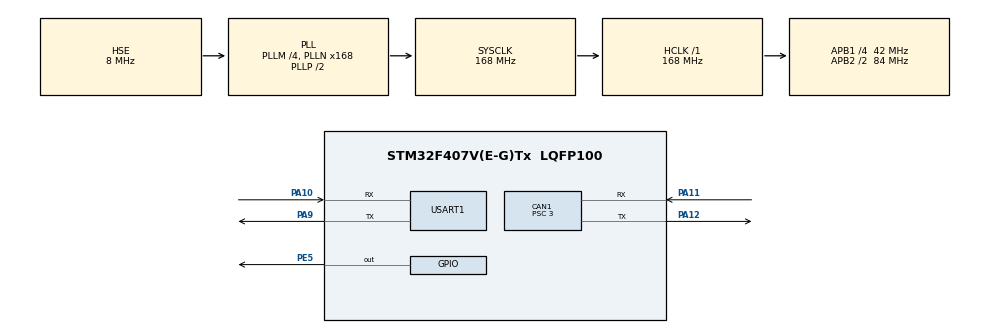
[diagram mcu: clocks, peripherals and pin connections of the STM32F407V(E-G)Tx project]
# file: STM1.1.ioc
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CAN1.BS1=CAN_BS1_10TQ
CAN1.BS2=CAN_BS2_3TQ
CAN1.CalculateBaudRate=1000000
CAN1.CalculateTimeBit=1000
CAN1.CalculateTimeQuantum=71.42857142857143
CAN1.Mode=CAN_MODE_SILENT_LOOPBACK
CAN1.Prescaler=3
Mcu.Family=STM32F4
Mcu.Name=STM32F407V(E-G)Tx
Mcu.Package=LQFP100
NVIC.CAN1_RX0_IRQn=true\:0\:0\:false\:false\:true\:true\:true\:true
NVIC.CAN1_TX_IRQn=true\:0\:0\:false\:false\:true\:true\:true\:true
NVIC.PriorityGroup=NVIC_PRIORITYGROUP_4
NVIC.USART1_IRQn=true\:0\:0\:false\:false\:true\:true\:true\:true
PA10.Mode=Asynchronous
PA10.Signal=USART1_RX
PA11.Mode=CAN_Activate
PA11.Signal=CAN1_RX
PA12.Mode=CAN_Activate
PA12.Signal=CAN1_TX
PA13.Mode=Serial_Wire
PA13.Signal=SYS_JTMS-SWDIO
PA14.Mode=Serial_Wire
PA14.Signal=SYS_JTCK-SWCLK
PA9.Mode=Asynchronous
PA9.Signal=USART1_TX
PE5.Signal=GPIO_Output
PH0-OSC_IN.Mode=HSE-External-Oscillator
PH0-OSC_IN.Signal=RCC_OSC_IN
PH1-OSC_OUT.Mode=HSE-External-Oscillator
PH1-OSC_OUT.Signal=RCC_OSC_OUT
ProjectManager.HeapSize=0x200
ProjectManager.StackSize=0x400
ProjectManager.TargetToolchain=CMake
RCC.48MHZClocksFreq_Value=84000000
RCC.AHBFreq_Value=168000000
RCC.APB1CLKDivider=RCC_HCLK_DIV4
RCC.APB1Freq_Value=42000000
RCC.APB1TimFreq_Value=84000000
RCC.APB2CLKDivider=RCC_HCLK_DIV2
RCC.APB2Freq_Value=84000000
RCC.APB2TimFreq_Value=168000000
RCC.CortexFreq_Value=168000000
RCC.HCLKFreq_Value=168000000
RCC.HSE_VALUE=8000000
RCC.HSI_VALUE=16000000
RCC.LSE_VALUE=32768
RCC.PLLM=4
RCC.PLLN=168
RCC.PLLSourceVirtual=RCC_PLLSOURCE_HSE
RCC.SYSCLKFreq_VALUE=168000000
RCC.SYSCLKSource=RCC_SYSCLKSOURCE_PLLCLK
RCC.VCOOutputFreq_Value=336000000
TIM9.Period=250-1
TIM9.Prescaler=84-1
USART1.VirtualMode=VM_ASYNC
VP_TIM9_VS_ClockSourceINT.Mode=Internal
board=custom

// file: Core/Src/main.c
/* USER CODE BEGIN Header */
/**
  ******************************************************************************
  * @file           : main.c
  * @brief          : Main program body
  ******************************************************************************
  * @attention
  *
  * Copyright (c) 2026 STMicroelectronics.
  * All rights reserved.
  *
  * This software is licensed under terms that can be found in the LICENSE file
  * in the root directory of this software component.
  * If no LICENSE file comes with this software, it is provided AS-IS.
  *
  ******************************************************************************
  */
/* USER CODE END Header */
#include "main.h"
#include "can.h"
#include "tim.h"
#include "usart.h"
#include "gpio.h"

/* USER CODE BEGIN PV */
// uint8_t receiveData [2];
/* USER CODE END PV */

void SystemClock_Config(void);

/* USER CODE BEGIN 0 */
// void HAL_UART_RxCpltCallback(UART_HandleTypeDef *huart){
//   HAL_UART_Transmit_IT(&huart1, receiveData, 2);
//     GPIO_PinState state = GPIO_PIN_SET;
//     if (receiveData[1] == '0')
//     {
//       state = GPIO_PIN_RESET;
//     }
//     if (receiveData[0] == 'R')
//     {
//       HAL_GPIO_WritePin(LED_RED_GPIO_Port, LED_RED_Pin, state);

//     }
//     else if (receiveData[0] == 'G')
//     {
//       HAL_GPIO_WritePin(LED_GREEN_GPIO_Port, LED_GREEN_Pin, state);
//     }
//     HAL_UART_Receive_IT(&huart1, receiveData, 2);
// }

/* USER CODE END 0 */

int main(void)
{

  /* MCU Configuration--------------------------------------------------------*/

  /* Reset of all peripherals, Initializes the Flash interface and the Systick. */
  HAL_Init();

  /* Configure the system clock */
  SystemClock_Config();

  /* Initialize all configured peripherals */
  MX_GPIO_Init();
  MX_TIM9_Init();
  MX_USART1_UART_Init();
  MX_CAN1_Init();
  /* USER CODE BEGIN 2 */
  // HAL_UART_Receive_IT(&huart1, receiveData, 2);

  CAN_TxHeaderTypeDef txHeader = {0};
  txHeader.StdId = 0x713;// TODO 对吗
  txHeader.ExtId = 0;// TODO对吗
  txHeader.IDE = CAN_ID_STD;// TODO 不对吧
  txHeader.RTR = CAN_RTR_DATA;//TODO 要改吗
  txHeader.DLC = 6;// TODO 要改吗
  txHeader.TransmitGlobalTime = DISABLE;
  /* 0x201 M2006 current, big-endian int16, range typically [-10000, 10000] */
  uint8_t txData[8] = {};// TODO 构造控制电机的CAN帧。建议电流值：1000
  uint32_t txMailbox;
  /* USER CODE END 2 */

  /* Infinite loop */
  /* USER CODE BEGIN WHILE */

  while (1)
  {
    // HAL_GPIO_WritePin(GPIOE, GPIO_PIN_6, GPIO_PIN_SET);
    // HAL_UART_Transmit(&huart1, (uint8_t*)message, sizeof(message) - 1,100);
    // HAL_Delay(1000);
    // HAL_UART_Receive(&huart1, receiveData, 2, HAL_MAX_DEYAL);
    // HAL_UART_Transmit(&huart1, receiveData, 2, 100);

//     for (int i = 0; i < 250; i++)
//     {
//       __HAL_TIM_SET_COMPARE(&htim9, TIM_CHANNEL_1, i);
//       HAL_Delay(10);
//     }
//     for (int i = 250 ; i > 0; i--)
//     {
//       __HAL_TIM_SET_COMPARE(&htim9, TIM_CHANNEL_1, i);
//       HAL_Delay(10);
//     }

    (void)HAL_CAN_AddTxMessage(&hcan1, &txHeader, txData, &txMailbox);

    HAL_Delay(1000); // TODO 电机的控制频率建议100hz

    /* USER CODE END WHILE */

  }
}

void SystemClock_Config(void)
{
  RCC_OscInitTypeDef RCC_OscInitStruct = {0};
  RCC_ClkInitTypeDef RCC_ClkInitStruct = {0};

  /** Configure the main internal regulator output voltage
  */
  __HAL_RCC_PWR_CLK_ENABLE();
  __HAL_PWR_VOLTAGESCALING_CONFIG(PWR_REGULATOR_VOLTAGE_SCALE1);

  /** Initializes the RCC Oscillators according to the specified parameters
  * in the RCC_OscInitTypeDef structure.
  */
  RCC_OscInitStruct.OscillatorType = RCC_OSCILLATORTYPE_HSE;
  RCC_OscInitStruct.HSEState = RCC_HSE_ON;
  RCC_OscInitStruct.PLL.PLLState = RCC_PLL_ON;
  RCC_OscInitStruct.PLL.PLLSource = RCC_PLLSOURCE_HSE;
  RCC_OscInitStruct.PLL.PLLM = 4;
  RCC_OscInitStruct.PLL.PLLN = 168;
  RCC_OscInitStruct.PLL.PLLP = RCC_PLLP_DIV2;
  RCC_OscInitStruct.PLL.PLLQ = 4;
  if (HAL_RCC_OscConfig(&RCC_OscInitStruct) != HAL_OK)
  {
    Error_Handler();
  }

  /** Initializes the CPU, AHB and APB buses clocks
  */
  RCC_ClkInitStruct.ClockType = RCC_CLOCKTYPE_HCLK|RCC_CLOCKTYPE_SYSCLK
                              |RCC_CLOCKTYPE_PCLK1|RCC_CLOCKTYPE_PCLK2;
  RCC_ClkInitStruct.SYSCLKSource = RCC_SYSCLKSOURCE_PLLCLK;
  RCC_ClkInitStruct.AHBCLKDivider = RCC_SYSCLK_DIV1;
  RCC_ClkInitStruct.APB1CLKDivider = RCC_HCLK_DIV4;
  RCC_ClkInitStruct.APB2CLKDivider = RCC_HCLK_DIV2;

  if (HAL_RCC_ClockConfig(&RCC_ClkInitStruct, FLASH_LATENCY_5) != HAL_OK)
  {
    Error_Handler();
  }
}

void Error_Handler(void)
{
  __disable_irq();
  while (1)
  {
  }
}
